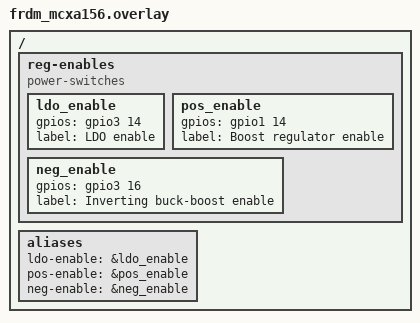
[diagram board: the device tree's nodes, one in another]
/ {
    reg-enables {
        compatible = "power-switches";
        ldo_enable: ldo_enable {
            gpios = <&gpio3 14 GPIO_ACTIVE_HIGH>;
            label = "LDO enable";
        };
        pos_enable: pos_enable {
            gpios = <&gpio1 14 GPIO_ACTIVE_HIGH>;
            label = "Boost regulator enable";
        };
        neg_enable: neg_enable {
            gpios = <&gpio3 16 GPIO_ACTIVE_HIGH>;
            label = "Inverting buck-boost enable";
        };
    };

    aliases {
        ldo-enable = &ldo_enable;
        pos-enable = &pos_enable;
        neg-enable = &neg_enable;
    };
};
